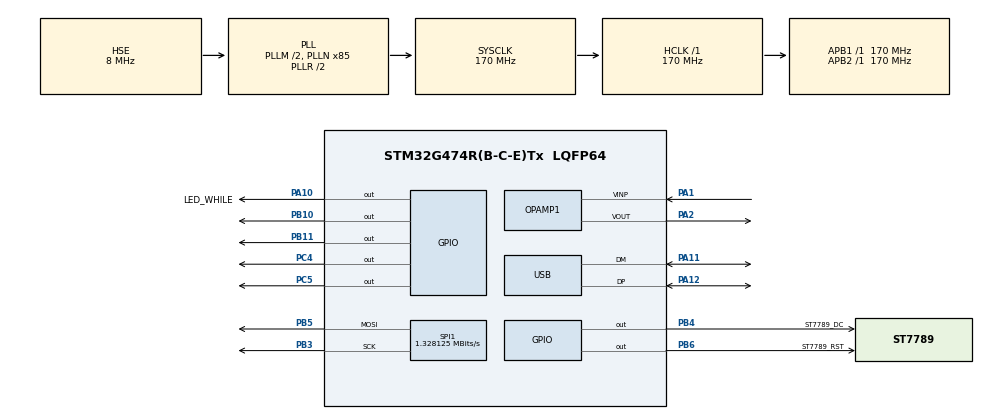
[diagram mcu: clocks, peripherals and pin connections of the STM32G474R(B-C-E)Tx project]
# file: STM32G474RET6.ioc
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Mcu.Family=STM32G4
Mcu.Name=STM32G474R(B-C-E)Tx
Mcu.Package=LQFP64
NVIC.PriorityGroup=NVIC_PRIORITYGROUP_4
NVIC.USB_LP_IRQn=true\:0\:0\:false\:false\:true\:false\:true\:true
OPAMP1.PowerMode=OPAMP_POWERMODE_HIGHSPEED
PA1.Mode=Follower
PA1.Signal=OPAMP1_VINP
PA10.GPIO_Label=LED_WHILE
PA10.Signal=GPIO_Output
PA11.Mode=Device
PA11.Signal=USB_DM
PA12.Mode=Device
PA12.Signal=USB_DP
PA13.Mode=Serial_Wire
PA13.Signal=SYS_JTMS-SWDIO
PA14.Mode=Serial_Wire
PA14.Signal=SYS_JTCK-SWCLK
PA2.Mode=Follower
PA2.Signal=OPAMP1_VOUT
PB10.Signal=GPIO_Output
PB11.Signal=GPIO_Output
PB3.Mode=TX_Only_Simplex_Unidirect_Master
PB3.Signal=SPI1_SCK
PB4.GPIO_Label=ST7789_DC
PB4.Signal=GPIO_Output
PB5.Mode=TX_Only_Simplex_Unidirect_Master
PB5.Signal=SPI1_MOSI
PB6.GPIO_Label=ST7789_RST
PB6.Signal=GPIO_Output
PC14-OSC32_IN.Mode=LSE-External-Oscillator
PC14-OSC32_IN.Signal=RCC_OSC32_IN
PC15-OSC32_OUT.Mode=LSE-External-Oscillator
PC15-OSC32_OUT.Signal=RCC_OSC32_OUT
PC4.GPIO_ModeDefaultOutputPP=GPIO_MODE_OUTPUT_PP
PC4.GPIO_PuPd=GPIO_PULLUP
PC4.Signal=GPIO_Output
PC5.GPIO_PuPd=GPIO_PULLUP
PC5.Signal=GPIO_Output
PF0-OSC_IN.Mode=HSE-External-Oscillator
PF0-OSC_IN.Signal=RCC_OSC_IN
PF1-OSC_OUT.Mode=HSE-External-Oscillator
PF1-OSC_OUT.Signal=RCC_OSC_OUT
ProjectManager.HeapSize=0x200
ProjectManager.StackSize=0x400
ProjectManager.TargetToolchain=STM32CubeIDE
RCC.ADC12Freq_Value=170000000
RCC.ADC345Freq_Value=170000000
RCC.AHBFreq_Value=170000000
RCC.APB1Freq_Value=170000000
RCC.APB1TimFreq_Value=170000000
RCC.APB2Freq_Value=170000000
RCC.APB2TimFreq_Value=170000000
RCC.CK48CLockSelection=RCC_USBCLKSOURCE_HSI48
RCC.CortexFreq_Value=170000000
RCC.EXTERNAL_CLOCK_VALUE=12288000
RCC.HCLKFreq_Value=170000000
RCC.HSE_VALUE=8000000
RCC.HSI48_VALUE=48000000
RCC.HSI_VALUE=16000000
RCC.PLLM=RCC_PLLM_DIV2
RCC.PLLN=85
RCC.PLLSourceVirtual=RCC_PLLSOURCE_HSE
RCC.RCC_MCO1Source=RCC_MCO1SOURCE_HSE
RCC.SYSCLKFreq_VALUE=170000000
RCC.SYSCLKSource=RCC_SYSCLKSOURCE_PLLCLK
RCC.USBFreq_Value=48000000
RCC.VCOOutputFreq_Value=340000000
SPI1.BaudRatePrescaler=SPI_BAUDRATEPRESCALER_128
SPI1.CalculateBaudRate=1.328125 MBits/s
SPI1.Direction=SPI_DIRECTION_2LINES
SPI1.Mode=SPI_MODE_MASTER
SPI1.VirtualType=VM_MASTER
SYS.VoltageScaling=SYSCFG_VREFBUF_VOLTAGE_SCALE0
USB_DEVICE.CLASS_NAME_FS=CDC
USB_DEVICE.VirtualMode=Cdc
USB_DEVICE.VirtualModeFS=Cdc_FS
VP_FMAC_VS_FMAC.Mode=FMAC_Activate
VP_RTC_VS_RTC_Activate.Mode=RTC_Enabled
VP_SYS_VS_DBSignals.Mode=DisableDeadBatterySignals
VP_USB_DEVICE_VS_USB_DEVICE_CDC_FS.Mode=CDC_FS
VREF+.Mode=InternalMode
VREF+.Signal=VREFBUF_OUT
board=custom

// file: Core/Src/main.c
/* USER CODE BEGIN Header */
/* USER CODE END Header */
#include "main.h"
#include "usb_device.h"

/* USER CODE BEGIN Includes */

#include "st7789.h"
#include "fonts.h"

/* USER CODE END Includes */

FMAC_HandleTypeDef hfmac;

OPAMP_HandleTypeDef hopamp1;

RTC_HandleTypeDef hrtc;

SPI_HandleTypeDef hspi1;

void SystemClock_Config(void);
static void MX_GPIO_Init(void);
static void MX_RTC_Init(void);
static void MX_OPAMP1_Init(void);
static void MX_FMAC_Init(void);
static void MX_SPI1_Init(void);

int main(void)
{

  /* MCU Configuration--------------------------------------------------------*/

  /* Reset of all peripherals, Initializes the Flash interface and the Systick. */
  HAL_Init();

  /* Configure the system clock */
  SystemClock_Config();

  /* Initialize all configured peripherals */
  MX_GPIO_Init();
  MX_RTC_Init();
  MX_USB_Device_Init();
  MX_OPAMP1_Init();
  MX_FMAC_Init();
  MX_SPI1_Init();

  /* Infinite loop */
  /* USER CODE BEGIN WHILE */

//  HAL_OPAMP_Start(&hopamp1);
//  ST7789_Init();
//  HAL_Delay(2000);
//  ST7789_Test();

  while(1){
  }

  HAL_Delay(1000);

  HAL_GPIO_WritePin(GPIOC, GPIO_PIN_4, 1);
  HAL_GPIO_WritePin(GPIOC, GPIO_PIN_5, 1);
  HAL_GPIO_WritePin(GPIOB, GPIO_PIN_10, 1);
  HAL_GPIO_WritePin(GPIOB, GPIO_PIN_11, 1);

  HAL_Delay(1000);

  HAL_GPIO_WritePin(GPIOC, GPIO_PIN_4, 0);
  HAL_GPIO_WritePin(GPIOC, GPIO_PIN_5, 0);
  HAL_GPIO_WritePin(GPIOB, GPIO_PIN_10, 0);
  HAL_GPIO_WritePin(GPIOB, GPIO_PIN_11, 0);
    /* USER CODE END WHILE */

}

void SystemClock_Config(void)
{
  RCC_OscInitTypeDef RCC_OscInitStruct = {0};
  RCC_ClkInitTypeDef RCC_ClkInitStruct = {0};

  /** Configure the main internal regulator output voltage
  */
  HAL_PWREx_ControlVoltageScaling(PWR_REGULATOR_VOLTAGE_SCALE1_BOOST);

  /** Initializes the RCC Oscillators according to the specified parameters
  * in the RCC_OscInitTypeDef structure.
  */
  RCC_OscInitStruct.OscillatorType = RCC_OSCILLATORTYPE_HSI48|RCC_OSCILLATORTYPE_LSI
                              |RCC_OSCILLATORTYPE_HSE;
  RCC_OscInitStruct.HSEState = RCC_HSE_ON;
  RCC_OscInitStruct.LSIState = RCC_LSI_ON;
  RCC_OscInitStruct.HSI48State = RCC_HSI48_ON;
  RCC_OscInitStruct.PLL.PLLState = RCC_PLL_ON;
  RCC_OscInitStruct.PLL.PLLSource = RCC_PLLSOURCE_HSE;
  RCC_OscInitStruct.PLL.PLLM = RCC_PLLM_DIV2;
  RCC_OscInitStruct.PLL.PLLN = 85;
  RCC_OscInitStruct.PLL.PLLP = RCC_PLLP_DIV2;
  RCC_OscInitStruct.PLL.PLLQ = RCC_PLLQ_DIV2;
  RCC_OscInitStruct.PLL.PLLR = RCC_PLLR_DIV2;
  if (HAL_RCC_OscConfig(&RCC_OscInitStruct) != HAL_OK)
  {
    Error_Handler();
  }

  /** Initializes the CPU, AHB and APB buses clocks
  */
  RCC_ClkInitStruct.ClockType = RCC_CLOCKTYPE_HCLK|RCC_CLOCKTYPE_SYSCLK
                              |RCC_CLOCKTYPE_PCLK1|RCC_CLOCKTYPE_PCLK2;
  RCC_ClkInitStruct.SYSCLKSource = RCC_SYSCLKSOURCE_PLLCLK;
  RCC_ClkInitStruct.AHBCLKDivider = RCC_SYSCLK_DIV1;
  RCC_ClkInitStruct.APB1CLKDivider = RCC_HCLK_DIV1;
  RCC_ClkInitStruct.APB2CLKDivider = RCC_HCLK_DIV1;

  if (HAL_RCC_ClockConfig(&RCC_ClkInitStruct, FLASH_LATENCY_4) != HAL_OK)
  {
    Error_Handler();
  }
}

static void MX_FMAC_Init(void)
{

  hfmac.Instance = FMAC;
  if (HAL_FMAC_Init(&hfmac) != HAL_OK)
  {
    Error_Handler();
  }

}

static void MX_OPAMP1_Init(void)
{

  hopamp1.Instance = OPAMP1;
  hopamp1.Init.PowerMode = OPAMP_POWERMODE_HIGHSPEED;
  hopamp1.Init.Mode = OPAMP_FOLLOWER_MODE;
  hopamp1.Init.NonInvertingInput = OPAMP_NONINVERTINGINPUT_IO0;
  hopamp1.Init.InternalOutput = DISABLE;
  hopamp1.Init.TimerControlledMuxmode = OPAMP_TIMERCONTROLLEDMUXMODE_DISABLE;
  hopamp1.Init.UserTrimming = OPAMP_TRIMMING_FACTORY;
  if (HAL_OPAMP_Init(&hopamp1) != HAL_OK)
  {
    Error_Handler();
  }

}

static void MX_RTC_Init(void)
{

  /** Initialize RTC Only
  */
  hrtc.Instance = RTC;
  hrtc.Init.HourFormat = RTC_HOURFORMAT_24;
  hrtc.Init.AsynchPrediv = 127;
  hrtc.Init.SynchPrediv = 255;
  hrtc.Init.OutPut = RTC_OUTPUT_DISABLE;
  hrtc.Init.OutPutRemap = RTC_OUTPUT_REMAP_NONE;
  hrtc.Init.OutPutPolarity = RTC_OUTPUT_POLARITY_HIGH;
  hrtc.Init.OutPutType = RTC_OUTPUT_TYPE_OPENDRAIN;
  hrtc.Init.OutPutPullUp = RTC_OUTPUT_PULLUP_NONE;
  if (HAL_RTC_Init(&hrtc) != HAL_OK)
  {
    Error_Handler();
  }

}

static void MX_SPI1_Init(void)
{

  /* SPI1 parameter configuration*/
  hspi1.Instance = SPI1;
  hspi1.Init.Mode = SPI_MODE_MASTER;
  hspi1.Init.Direction = SPI_DIRECTION_2LINES;
  hspi1.Init.DataSize = SPI_DATASIZE_4BIT;
  hspi1.Init.CLKPolarity = SPI_POLARITY_LOW;
  hspi1.Init.CLKPhase = SPI_PHASE_1EDGE;
  hspi1.Init.NSS = SPI_NSS_SOFT;
  hspi1.Init.BaudRatePrescaler = SPI_BAUDRATEPRESCALER_128;
  hspi1.Init.FirstBit = SPI_FIRSTBIT_MSB;
  hspi1.Init.TIMode = SPI_TIMODE_DISABLE;
  hspi1.Init.CRCCalculation = SPI_CRCCALCULATION_DISABLE;
  hspi1.Init.CRCPolynomial = 7;
  hspi1.Init.CRCLength = SPI_CRC_LENGTH_DATASIZE;
  hspi1.Init.NSSPMode = SPI_NSS_PULSE_ENABLE;
  if (HAL_SPI_Init(&hspi1) != HAL_OK)
  {
    Error_Handler();
  }

}

static void MX_GPIO_Init(void)
{
  GPIO_InitTypeDef GPIO_InitStruct = {0};

  /* GPIO Ports Clock Enable */
  __HAL_RCC_GPIOC_CLK_ENABLE();
  __HAL_RCC_GPIOF_CLK_ENABLE();
  __HAL_RCC_GPIOA_CLK_ENABLE();
  __HAL_RCC_GPIOB_CLK_ENABLE();

  /*Configure GPIO pin Output Level */
  HAL_GPIO_WritePin(GPIOC, GPIO_PIN_4|GPIO_PIN_5, GPIO_PIN_RESET);

  /*Configure GPIO pin Output Level */
  HAL_GPIO_WritePin(GPIOB, GPIO_PIN_10|GPIO_PIN_11|ST7789_DC_Pin|ST7789_RST_Pin, GPIO_PIN_RESET);

  /*Configure GPIO pin Output Level */
  HAL_GPIO_WritePin(LED_WHILE_GPIO_Port, LED_WHILE_Pin, GPIO_PIN_RESET);

  /*Configure GPIO pins : PC4 PC5 */
  GPIO_InitStruct.Pin = GPIO_PIN_4|GPIO_PIN_5;
  GPIO_InitStruct.Mode = GPIO_MODE_OUTPUT_PP;
  GPIO_InitStruct.Pull = GPIO_PULLUP;
  GPIO_InitStruct.Speed = GPIO_SPEED_FREQ_LOW;
  HAL_GPIO_Init(GPIOC, &GPIO_InitStruct);

  /*Configure GPIO pins : PB10 PB11 ST7789_DC_Pin ST7789_RST_Pin */
  GPIO_InitStruct.Pin = GPIO_PIN_10|GPIO_PIN_11|ST7789_DC_Pin|ST7789_RST_Pin;
  GPIO_InitStruct.Mode = GPIO_MODE_OUTPUT_PP;
  GPIO_InitStruct.Pull = GPIO_NOPULL;
  GPIO_InitStruct.Speed = GPIO_SPEED_FREQ_LOW;
  HAL_GPIO_Init(GPIOB, &GPIO_InitStruct);

  /*Configure GPIO pin : LED_WHILE_Pin */
  GPIO_InitStruct.Pin = LED_WHILE_Pin;
  GPIO_InitStruct.Mode = GPIO_MODE_OUTPUT_PP;
  GPIO_InitStruct.Pull = GPIO_NOPULL;
  GPIO_InitStruct.Speed = GPIO_SPEED_FREQ_LOW;
  HAL_GPIO_Init(LED_WHILE_GPIO_Port, &GPIO_InitStruct);

}

void Error_Handler(void)
{
}
